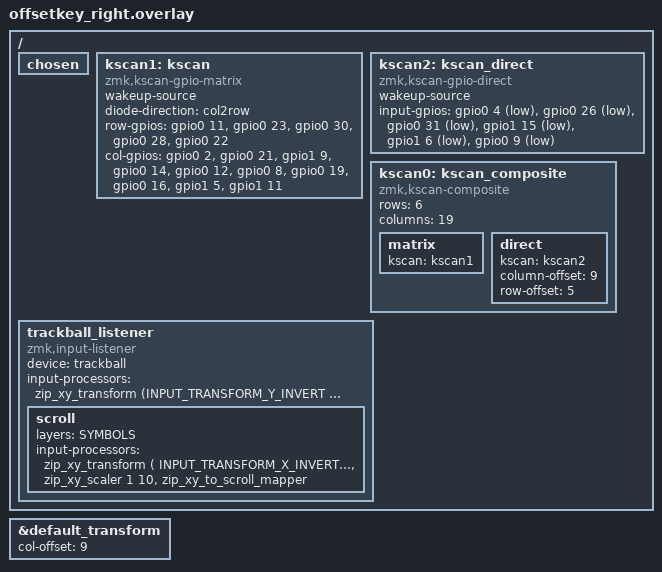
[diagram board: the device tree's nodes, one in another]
/*
 * Copyright (c) 2020 ZMK Contributors
 *
 * SPDX-License-Identifier: MIT
 */
#include <dt-bindings/zmk/input_transform.h>
#include <input/processors.dtsi>
#include <dt-bindings/led/led.h>
#include "offsetkey.dtsi"
//#include "trackball.dtsi"
#include "split_inputs.dtsi"
#include "trackpoint.dtsi"
#define SYMBOLS 2

//#include "rgb.dtsi"

/ {
	chosen {
       // zmk,underglow = &led_strip;
    };

    kscan1: kscan {
        wakeup-source;
        diode-direction = "col2row";
        compatible = "zmk,kscan-gpio-matrix";
        row-gpios
            = <&gpio0 11 (GPIO_ACTIVE_HIGH | GPIO_PULL_DOWN)>
            , <&gpio0 23 (GPIO_ACTIVE_HIGH | GPIO_PULL_DOWN)>
            , <&gpio0 30  (GPIO_ACTIVE_HIGH | GPIO_PULL_DOWN)>
            , <&gpio0 28 (GPIO_ACTIVE_HIGH | GPIO_PULL_DOWN)>
            , <&gpio0 22 (GPIO_ACTIVE_HIGH | GPIO_PULL_DOWN)>
            ;
        col-gpios
            =  <&gpio0 2  GPIO_ACTIVE_HIGH>
            ,  <&gpio0 21  GPIO_ACTIVE_HIGH>
            , <&gpio1 9  GPIO_ACTIVE_HIGH>
            , <&gpio0 14  GPIO_ACTIVE_HIGH>
            , <&gpio0 12  GPIO_ACTIVE_HIGH>
            , <&gpio0 8  GPIO_ACTIVE_HIGH>  
            , <&gpio0 19  GPIO_ACTIVE_HIGH>  
            , <&gpio0 16  GPIO_ACTIVE_HIGH>  
            , <&gpio1 5  GPIO_ACTIVE_HIGH> 
            , <&gpio1 11 GPIO_ACTIVE_HIGH> 
            ;
    };

    kscan2: kscan_direct {
        compatible = "zmk,kscan-gpio-direct";
        wakeup-source;
        input-gpios
            = <&gpio0 4 (GPIO_ACTIVE_LOW | GPIO_PULL_UP)>
            , <&gpio0 26 (GPIO_ACTIVE_LOW | GPIO_PULL_UP)>
            , <&gpio0 31 (GPIO_ACTIVE_LOW | GPIO_PULL_UP)>
            , <&gpio1 15 (GPIO_ACTIVE_LOW | GPIO_PULL_UP)>
            , <&gpio1 6 (GPIO_ACTIVE_LOW | GPIO_PULL_UP)>
            , <&gpio0 9 (GPIO_ACTIVE_LOW | GPIO_PULL_UP)>
            ;
    };
//only 1.04 1.07 remain
    kscan0: kscan_composite {
        compatible = "zmk,kscan-composite";
        rows = <6>;
        columns = <19>;

        // Include the matrix driver
        matrix {
            kscan = <&kscan1>;
        };

        // Include the direct GPIO driver...
        direct {
            kscan = <&kscan2>;
            column-offset = <9>;
            row-offset = <5>;
        };
    };
};

&default_transform {
	col-offset = <9>;
};






/ {
  trackball_listener: trackball_listener {
    compatible = "zmk,input-listener";
    status = "okay";
    device = <&trackball>;
    input-processors = <&zip_xy_transform (INPUT_TRANSFORM_Y_INVERT | INPUT_TRANSFORM_X_INVERT | INPUT_TRANSFORM_XY_SWAP )>;
    scroll {
      layers = <SYMBOLS>;
      input-processors = <&zip_xy_transform ( INPUT_TRANSFORM_X_INVERT | INPUT_TRANSFORM_XY_SWAP)>, <&zip_xy_scaler 1 10>, <&zip_xy_to_scroll_mapper>;
    };
  };
}; 
